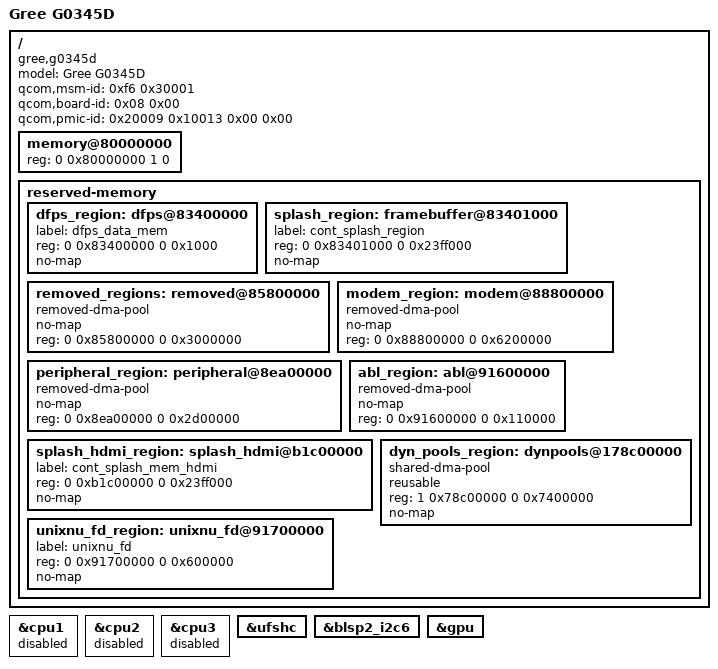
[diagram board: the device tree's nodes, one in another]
// SPDX-License-Identifier: BSD-3-Clause
// UniXNU board description for the Gree G0345D (格力手机 G3).
// Shared MSM8996 resources come from msm8996.dtsi.
//
// Board facts (stock QFIL package + published stock DTS
// g0345d-msm8996-v3.1.dts + on-hardware verification 2026-11-14):
//   SoC      Qualcomm Snapdragon 820 (MSM8996 v3.1), 4x Kryo
//   RAM      4 GB LPDDR4, DRAM base 0x80000000
//   Storage  64 GB UFS 2.0, 4096 B LBA, 6 LUNs
//   Display  1080x2160 DSI video panel, 60 fps, 24 bpp, 4 lanes
//            (scanout verified on hardware: stride 3240 B, UEFI PCD
//            PcdMipiFrameBuffer 1080x2160x24; stock DTS lists a Dual SHARP
//            video-mode panel among its candidates)
//   UART     BLSP2 UART2 console=ttyHSL0,115200 (SoC default, unverified)
//   Splash   cont_splash_mem @ 0x83401000, size 0x23ff000 (36 MB) [stock DTS]
//
// Handoff memory map at BootShim entry (all firmware-owned regions stay
// reserved for UniXNU; LK DTB seen at 0x83300000 store slot, DTB itself
// passed in x0):
//   0x80008000-0x81c03570  kernel image load window (BootShim+FD land here)
//   0x81000000..           ramdisk slot load address (stock 8.3 MB; payload
//                          FAT 24 MiB verified 2026-11-14)
//   0x83300000             LK DTB store slot (PcdDeviceTreeStore)
//   0x83400000-0x83401000  dfps_data_mem [stock DTS, 4 KB]
//   0x83401000-0x85800000  cont_splash_mem (panel framebuffer handoff)
//   0x85800000-0x88800000  removed_regions (TZ high + SMEM)
//   0x88800000-0x8ea00000  modem_region (NON-HLOS.bin, TZ-loaded)
//   0x8ea00000-0x91700000  peripheral_region (stock size 0x2d00000)
//   0x91600000-0x91700000  aboot (emmc_appsboot.mbn, 1 MiB partition, running)
//   0x91700000-0x91d00000  UniXNU UEFI FV (FD_BASE=0x91700000, FD_SIZE=0x600000)
//   0xb1c00000-0xb3fff000  cont_splash_mem_hdmi (stock reservation)
//   0x178c00000-0x180000000  dynamic DMA pools (adsp 4M + qseecom 20M +
//                           secure 92M), carved from the top of 4 GB in stock
/dts-v1/;
/include/ "msm8996.dtsi"

/ {
    model = "Gree G0345D";
    compatible = "gree,g0345d", "qcom,msm8996";

    // SoC/board identification, verbatim from the stock DTS root.
    // aboot scans the appended DTB table and selects the entry whose
    // qcom,msm-id / qcom,board-id / qcom,pmic-id match the device.
    // These three properties must stay or the bootloader refuses the tree.
    // [g0345d stock values; g0245d differs: board-id 0x03, msm v3.0]
    qcom,msm-id = <0xf6 0x30001>;
    qcom,board-id = <0x08 0x00>;
    qcom,pmic-id = <0x20009 0x10013 0x00 0x00>;

    // 4 GB LPDDR4 at the MSM8996 standard DRAM base.
    memory@80000000 {
        device_type = "memory";
        reg = <0 0x80000000 1 0>;
    };

    reserved-memory {
        #address-cells = <2>;
        #size-cells = <2>;
        ranges;

        // dfps_data_mem@83400000, 4 KB (stock DTS) — DFPS iframe scratch.
        dfps_region: dfps@83400000 {
            label = "dfps_data_mem";
            reg = <0 0x83400000 0 0x1000>;
            no-map;
        };

        // Continuous splash framebuffer, verbatim from the stock DTS:
        //   cont_splash_mem@83401000, reg = <0x00 0x83401000 0x00 0x23ff000>
        // The stock ABL hands the panel framebuffer over at this address;
        // the UniXNU GopFramebuffer stage adopts it unchanged.
        splash_region: framebuffer@83401000 {
            label = "cont_splash_region";
            reg = <0 0x83401000 0 0x23ff000>;
            no-map;
        };

        // removed_regions@85800000, size 0x3000000 (stock DTS).
        // XBL/TZ high-DDR image and SMEM (0x86000000-0x86200000).
        removed_regions: removed@85800000 {
            compatible = "removed-dma-pool";
            no-map;
            reg = <0 0x85800000 0 0x3000000>;
        };

        // modem_region@88800000, size 0x6200000 (stock DTS).
        modem_region: modem@88800000 {
            compatible = "removed-dma-pool";
            no-map;
            reg = <0 0x88800000 0 0x6200000>;
        };

        // peripheral_region@8ea00000, size 0x2d00000 (stock DTS value; the
        // g0245d uses 0x2b00000 — this device reserves 2 MB more).
        // TZ runtime pool + aboot scratch; the boot.img header scratch
        // lives inside this region.
        peripheral_region: peripheral@8ea00000 {
            compatible = "removed-dma-pool";
            no-map;
            reg = <0 0x8ea00000 0 0x2d00000>;
        };

        // aboot resident image (emmc_appsboot.mbn): 1 MiB partition image,
        // loaded at 0x91600000 (REA: SCM entry FUN_9161b2bc in that range).
        // aboot is still running when BootShim starts; keep reserved.
        abl_region: abl@91600000 {
            compatible = "removed-dma-pool";
            no-map;
            reg = <0 0x91600000 0 0x110000>;
        };

        // cont_splash_mem_hdmi@b1c00000, size 0x23ff000 (stock reservation).
        splash_hdmi_region: splash_hdmi@b1c00000 {
            label = "cont_splash_mem_hdmi";
            reg = <0 0xb1c00000 0 0x23ff000>;
            no-map;
        };

        // Dynamic DMA pools from the stock DTS (shared-dma-pool, reusable):
        //   adsp_region 0x400000, qseecom_region 0x1400000,
        //   secure_region 0x5c00000 — carved from the top of the 4 GB window.
        dyn_pools_region: dynpools@178c00000 {
            compatible = "shared-dma-pool";
            reusable;
            reg = <1 0x78c00000 0 0x7400000>;
            no-map;
        };

        // UniXNU UEFI firmware volume destination. BootShim relocates the FD
        // here before entering UEFI. g0345d overlay FDF: FD base 0x91700000,
        // size 0x600000 (6 MiB), free window above aboot, below HDMI splash.
        unixnu_fd_region: unixnu_fd@91700000 {
            label = "unixnu_fd";
            reg = <0 0x91700000 0 0x600000>;
            no-map;
        };
    };
};

// Stage 1: boot CPU only. Enable cpu1..cpu3 after the GICv3 3-cell
// specifier check passes (same gating as g0245d).
&cpu1 { status = "disabled"; };
&cpu2 { status = "disabled"; };
&cpu3 { status = "disabled"; };

// Peripheral enablement: same three nodes as g0245d (each has a linked
// register-probe driver).  See the g0245d dts for the full enablement
// rationale and the hardware qualification notes.
&ufshc { status = "okay"; };
&blsp2_i2c6 { status = "okay"; };
&gpu { status = "okay"; };

// Deliberately NOT enabled yet (same list as g0245d): ufsphy, adreno_smmu,
// mdss/mdp/dsi0 (ranges translation issue), blsp2_uart2, pcie, usb3, cpu1..3.
